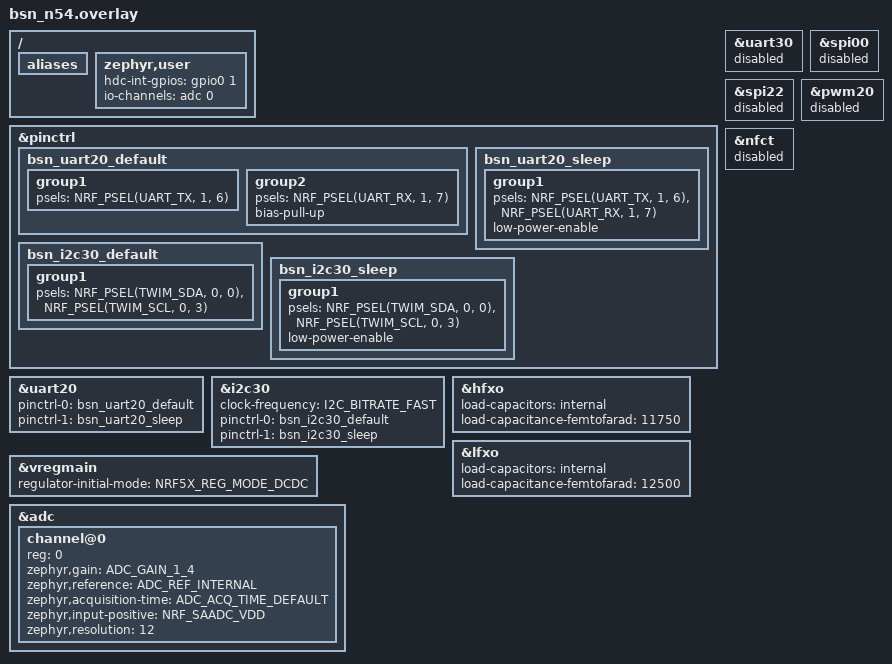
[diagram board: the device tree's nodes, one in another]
/*
 * bsn_n54.overlay - BSN-N54-A on top of the nrf54l15dk/nrf54l05/cpuapp board
 *
 * Source of truth: hardware/N54/BSN-N54.kicad_sch. Keep this file in sync with
 * the schematic and with common/bsn_board.h.
 *
 *  Signal      Pin    QFN  Test point  Notes
 *  ---------   -----  ---  ----------  -----------------------------------
 *  I2C SDA     P0.00  23   TP6         R2 4.7k pull-up to VDD
 *  I2C SCL     P0.03  28   TP7         R3 4.7k pull-up to VDD
 *  HDC_INT     P0.01  24   TP8         HDC2010 DRDY/INT (push-pull)
 *  UART TXD    P1.06  7    TP9         nRF54 TX -> USB-UART RX
 *  UART RXD    P1.07  8    TP10        nRF54 RX <- USB-UART TX
 *  SWDIO       SWDIO  25   TP3
 *  SWDCLK      SWDCLK 26   TP2
 *  nRESET      RESET  30               R1 1k, C13 100n
 *  XC1/XC2            34/35            X1 32 MHz (CX3225FB, CL 7 pF), no external caps
 *  XL1/XL2     P1.00/P1.01  1/2        X2 32.768 kHz (SC-32S), no external caps
 *  DCC                46               L1 4.7 uH -> DC/DC on
 *
 * The DK's LEDs, buttons, external flash (spi00), VCOM1 (uart30, which sits on
 * P0.00-P0.03 = our I2C pins), PWM LED and NFC are not on this board.
 *
 * P0 pins can only be routed to the serial instance 30 (low-power domain), so
 * the I2C bus uses i2c30 in place of uart30.
 */

#include <zephyr/dt-bindings/adc/nrf-saadc.h>

/ {
	aliases {
		/delete-property/ led0;
		/delete-property/ led1;
		/delete-property/ led2;
		/delete-property/ led3;
		/delete-property/ pwm-led0;
		/delete-property/ sw0;
		/delete-property/ sw1;
		/delete-property/ sw2;
		/delete-property/ sw3;
		/delete-property/ mcuboot-button0;
		/delete-property/ mcuboot-led0;
	};

	/delete-node/ leds;
	/delete-node/ pwmleds;
	/delete-node/ buttons;

	/* HDC2010 INT: push-pull, but high-Z until configured, so pulled down */
	zephyr,user {
		hdc-int-gpios = <&gpio0 1 (GPIO_PULL_DOWN | GPIO_ACTIVE_HIGH)>;
		io-channels = <&adc 0>;
	};
};

&pinctrl {
	bsn_uart20_default: bsn_uart20_default {
		group1 {
			psels = <NRF_PSEL(UART_TX, 1, 6)>;
		};

		group2 {
			psels = <NRF_PSEL(UART_RX, 1, 7)>;
			bias-pull-up;
		};
	};

	bsn_uart20_sleep: bsn_uart20_sleep {
		group1 {
			psels = <NRF_PSEL(UART_TX, 1, 6)>,
				<NRF_PSEL(UART_RX, 1, 7)>;
			low-power-enable;
		};
	};

	bsn_i2c30_default: bsn_i2c30_default {
		group1 {
			psels = <NRF_PSEL(TWIM_SDA, 0, 0)>,
				<NRF_PSEL(TWIM_SCL, 0, 3)>;
			/* External 4.7k pull-ups (R2/R3) */
		};
	};

	bsn_i2c30_sleep: bsn_i2c30_sleep {
		group1 {
			psels = <NRF_PSEL(TWIM_SDA, 0, 0)>,
				<NRF_PSEL(TWIM_SCL, 0, 3)>;
			low-power-enable;
		};
	};
};

&uart20 {
	pinctrl-0 = <&bsn_uart20_default>;
	pinctrl-1 = <&bsn_uart20_sleep>;
};

&uart30 {
	status = "disabled";
};

sensor_i2c: &i2c30 {
	status = "okay";
	clock-frequency = <I2C_BITRATE_FAST>;
	pinctrl-0 = <&bsn_i2c30_default>;
	pinctrl-1 = <&bsn_i2c30_sleep>;
	pinctrl-names = "default", "sleep";
};

&spi00 {
	status = "disabled";
};

/delete-node/ &mx25r64;

&spi22 {
	status = "disabled";
};

&pwm20 {
	status = "disabled";
};

&nfct {
	status = "disabled";
};

/* X1: CX3225FB 32 MHz (datasheet CL = 7 pF), internal load capacitors only.
 * Trimmed on board #2 with cwtest at 2440 MHz (2026-10-27): 7 pF gave +127 ppm,
 * 11.5 pF +8 ppm, 12.0 pF -4 ppm, 17 pF -72 ppm. 11.75 pF sits between the last two.
 * Override per build with HFXO_CL_FF=<fF>. */
&hfxo {
	load-capacitors = "internal";
	load-capacitance-femtofarad = <11750>;
};

/* X2: SC-32S 32.768 kHz, internal load capacitors only.
 * The SC-32S comes in 6 pF and 12.5 pF versions; 12.5 pF assumed (check the reel label). */
&lfxo {
	load-capacitors = "internal";
	load-capacitance-femtofarad = <12500>;
};

/* L1 (4.7 uH) is fitted on DCC, so the DK default (DC/DC) applies */
&vregmain {
	regulator-initial-mode = <NRF5X_REG_MODE_DCDC>;
};

/* Channel 0: VDD (the cell or bench supply), internal 0.9 V reference, gain 1/4 -> 3.6 V full scale */
&adc {
	#address-cells = <1>;
	#size-cells = <0>;

	channel@0 {
		reg = <0>;
		zephyr,gain = "ADC_GAIN_1_4";
		zephyr,reference = "ADC_REF_INTERNAL";
		zephyr,acquisition-time = <ADC_ACQ_TIME_DEFAULT>;
		zephyr,input-positive = <NRF_SAADC_VDD>;
		zephyr,resolution = <12>;
	};
};
